# ESP32-S3 register map
Vendor: ESPRESSIF SYSTEMS (SHANGHAI) CO., LTD.; Series: ESP32-S3; File version: 7
CPU: Xtensa LX7 r0p0, little endian, no MPU, FPU, 3 interrupt priority bits
Address unit: 32 bits
Registers are 32-bit, read-write, reset 0x0 unless marked. A register's access mark holds for its fields unless they carry their own. Offsets are from the block's base; [hi:lo] are bit positions; {n}, {i} and the like mark numbered series.

## UHCI0 — Universal Host Controller Interface
Base 0x60014000
Same registers: UHCI1 0x6000C000
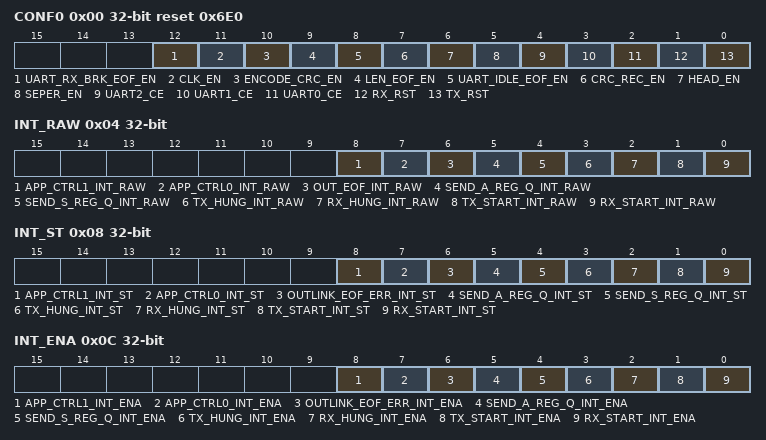
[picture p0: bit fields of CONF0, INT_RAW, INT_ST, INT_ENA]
0x00 CONF0 reset 0x6E0 — UHCI configuration register
  [12] UART_RX_BRK_EOF_EN — If this bit is set to 1, UHCI will end payload receive process when NULL frame is received by UART.
  [11] CLK_EN — 1'b1: Force clock on for register. 1'b0: Support clock only when application writes registers.
  [10] ENCODE_CRC_EN — Set this bit to enable data integrity checking by appending a 16 bit CCITT-CRC to end of the payload.
  [9] LEN_EOF_EN — If this bit is set to 1, UHCI decoder receiving payload data is end when the receiving byte count has reached the specified value. The value is payload length indicated by UHCI packet header when UHCI_HEAD_EN is 1 or the value is configuration value when UHCI_HEAD_EN is 0. If this bit is set to 0, UHCI decoder receiving payload data is end when 0xc0 is received.
  [8] UART_IDLE_EOF_EN — If this bit is set to 1, UHCI will end the payload receiving process when UART has been in idle state.
  [7] CRC_REC_EN — Set this bit to enable UHCI to receive the 16 bit CRC.
  [6] HEAD_EN — Set this bit to encode the data packet with a formatting header.
  [5] SEPER_EN — Set this bit to separate the data frame using a special char.
  [4] UART2_CE — Set this bit to link up HCI and UART2.
  [3] UART1_CE — Set this bit to link up HCI and UART1.
  [2] UART0_CE — Set this bit to link up HCI and UART0.
  [1] RX_RST — Write 1, then write 0 to this bit to reset encode state machine.
  [0] TX_RST — Write 1, then write 0 to this bit to reset decode state machine.
0x04 INT_RAW access per field — Raw interrupt status
  [8] APP_CTRL1_INT_RAW rw — This is the interrupt raw bit. Triggered when set UHCI_APP_CTRL1_IN_SET.
  [7] APP_CTRL0_INT_RAW rw — This is the interrupt raw bit. Triggered when set UHCI_APP_CTRL0_IN_SET.
  [6] OUT_EOF_INT_RAW ro — This is the interrupt raw bit. Triggered when there are some errors in EOF in the transmit data.
  [5] SEND_A_REG_Q_INT_RAW ro — This is the interrupt raw bit. Triggered when UHCI has sent out a short packet using always_send registers.
  [4] SEND_S_REG_Q_INT_RAW ro — This is the interrupt raw bit. Triggered when UHCI has sent out a short packet using single_send registers.
  [3] TX_HUNG_INT_RAW ro — This is the interrupt raw bit. Triggered when UHCI takes more time to read data from RAM than the configured value.
  [2] RX_HUNG_INT_RAW ro — This is the interrupt raw bit. Triggered when UHCI takes more time to receive data than configure value.
  [1] TX_START_INT_RAW ro — This is the interrupt raw bit. Triggered when UHCI detects a separator char.
  [0] RX_START_INT_RAW ro — This is the interrupt raw bit. Triggered when a separator char has been sent.
0x08 INT_ST ro — Masked interrupt status
  [8] APP_CTRL1_INT_ST — This is the masked interrupt bit for UHCI_APP_CTRL1_INT interrupt when UHCI_APP_CTRL1_INT_ENA is set to 1.
  [7] APP_CTRL0_INT_ST — This is the masked interrupt bit for UHCI_APP_CTRL0_INT interrupt when UHCI_APP_CTRL0_INT_ENA is set to 1.
  [6] OUTLINK_EOF_ERR_INT_ST — This is the masked interrupt bit for UHCI_OUTLINK_EOF_ERR_INT interrupt when UHCI_OUTLINK_EOF_ERR_INT_ENA is set to 1.
  [5] SEND_A_REG_Q_INT_ST — This is the masked interrupt bit for UHCI_SEND_A_REQ_Q_INT interrupt when UHCI_SEND_A_REQ_Q_INT_ENA is set to 1.
  [4] SEND_S_REG_Q_INT_ST — This is the masked interrupt bit for UHCI_SEND_S_REQ_Q_INT interrupt when UHCI_SEND_S_REQ_Q_INT_ENA is set to 1.
  [3] TX_HUNG_INT_ST — This is the masked interrupt bit for UHCI_TX_HUNG_INT interrupt when UHCI_TX_HUNG_INT_ENA is set to 1.
  [2] RX_HUNG_INT_ST — This is the masked interrupt bit for UHCI_RX_HUNG_INT interrupt when UHCI_RX_HUNG_INT_ENA is set to 1.
  [1] TX_START_INT_ST — This is the masked interrupt bit for UHCI_TX_START_INT interrupt when UHCI_TX_START_INT_ENA is set to 1.
  [0] RX_START_INT_ST — This is the masked interrupt bit for UHCI_RX_START_INT interrupt when UHCI_RX_START_INT_ENA is set to 1.
0x0C INT_ENA — Interrupt enable bits
  [8] APP_CTRL1_INT_ENA — This is the interrupt enable bit for UHCI_APP_CTRL1_INT interrupt.
  [7] APP_CTRL0_INT_ENA — This is the interrupt enable bit for UHCI_APP_CTRL0_INT interrupt.
  [6] OUTLINK_EOF_ERR_INT_ENA — This is the interrupt enable bit for UHCI_OUTLINK_EOF_ERR_INT interrupt.
  [5] SEND_A_REG_Q_INT_ENA — This is the interrupt enable bit for UHCI_SEND_A_REQ_Q_INT interrupt.
  [4] SEND_S_REG_Q_INT_ENA — This is the interrupt enable bit for UHCI_SEND_S_REQ_Q_INT interrupt.
  [3] TX_HUNG_INT_ENA — This is the interrupt enable bit for UHCI_TX_HUNG_INT interrupt.
  [2] RX_HUNG_INT_ENA — This is the interrupt enable bit for UHCI_RX_HUNG_INT interrupt.
  [1] TX_START_INT_ENA — This is the interrupt enable bit for UHCI_TX_START_INT interrupt.
  [0] RX_START_INT_ENA — This is the interrupt enable bit for UHCI_RX_START_INT interrupt.
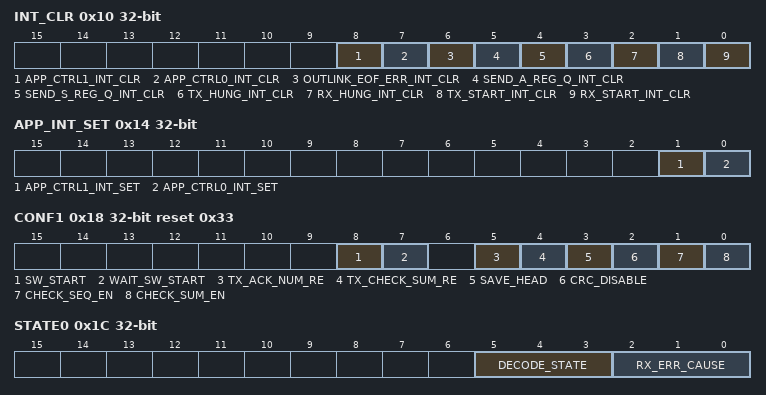
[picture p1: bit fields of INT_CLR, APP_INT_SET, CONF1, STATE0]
0x10 INT_CLR wo — Interrupt clear bits
  [8] APP_CTRL1_INT_CLR — Set this bit to clear UHCI_APP_CTRL1_INT interrupt.
  [7] APP_CTRL0_INT_CLR — Set this bit to clear UHCI_APP_CTRL0_INT interrupt.
  [6] OUTLINK_EOF_ERR_INT_CLR — Set this bit to clear UHCI_OUTLINK_EOF_ERR_INT interrupt.
  [5] SEND_A_REG_Q_INT_CLR — Set this bit to clear UHCI_SEND_A_REQ_Q_INT interrupt.
  [4] SEND_S_REG_Q_INT_CLR — Set this bit to clear UHCI_SEND_S_REQ_Q_INT interrupt.
  [3] TX_HUNG_INT_CLR — Set this bit to clear UHCI_TX_HUNG_INT interrupt.
  [2] RX_HUNG_INT_CLR — Set this bit to clear UHCI_RX_HUNG_INT interrupt.
  [1] TX_START_INT_CLR — Set this bit to clear UHCI_TX_START_INT interrupt.
  [0] RX_START_INT_CLR — Set this bit to clear UHCI_RX_START_INT interrupt.
0x14 APP_INT_SET wo — Software interrupt trigger source
  [1] APP_CTRL1_INT_SET — This bit is software interrupt trigger source of UHCI_APP_CTRL1_INT.
  [0] APP_CTRL0_INT_SET — This bit is software interrupt trigger source of UHCI_APP_CTRL0_INT.
0x18 CONF1 reset 0x33 — UHCI configuration register
  [8] SW_START — If current UHCI_ENCODE_STATE is ST_SW_WAIT, the UHCI will start to send data packet out when this bit is set to 1.
  [7] WAIT_SW_START — The uhci-encoder will jump to ST_SW_WAIT status if this register is set to 1.
  [5] TX_ACK_NUM_RE — Set this bit to encode the data packet with an acknowledgment when a reliable packet is to be transmit.
  [4] TX_CHECK_SUM_RE — Set this bit to encode the data packet with a checksum.
  [3] SAVE_HEAD — Set this bit to save the packet header when HCI receives a data packet.
  [2] CRC_DISABLE — Set this bit to support CRC calculation. Data Integrity Check Present bit in UHCI packet frame should be 1.
  [1] CHECK_SEQ_EN — This is the enable bit to check sequence number when UHCI receives a data packet.
  [0] CHECK_SUM_EN — This is the enable bit to check header checksum when UHCI receives a data packet.
0x1C STATE0 ro — UHCI receive status
  [5:3] DECODE_STATE — UHCI decoder status.
  [2:0] RX_ERR_CAUSE — This register indicates the error type when DMA has received a packet with error. 3'b001: Checksum error in HCI packet. 3'b010: Sequence number error in HCI packet. 3'b011: CRC bit error in HCI packet. 3'b100: 0xc0 is found but received HCI packet is not end. 3'b101: 0xc0 is not found when receiving HCI packet is end. 3'b110: CRC check error.
0x20 STATE1 ro — UHCI transmit status
  [2:0] ENCODE_STATE — UHCI encoder status.
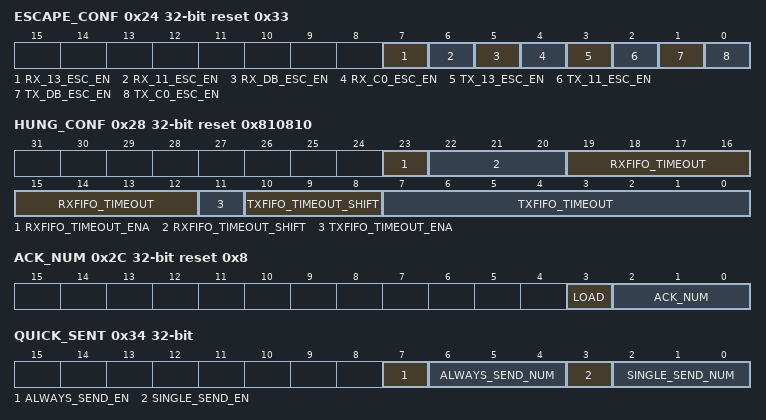
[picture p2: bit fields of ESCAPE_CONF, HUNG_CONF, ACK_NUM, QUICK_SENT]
0x24 ESCAPE_CONF reset 0x33 — Escape character configuration
  [7] RX_13_ESC_EN — Set this bit to enable replacing flow control char 0x13 by special char when DMA sends data.
  [6] RX_11_ESC_EN — Set this bit to enable replacing flow control char 0x11 by special char when DMA sends data.
  [5] RX_DB_ESC_EN — Set this bit to enable replacing 0xdb by special char when DMA sends data.
  [4] RX_C0_ESC_EN — Set this bit to enable replacing 0xc0 by special char when DMA sends data.
  [3] TX_13_ESC_EN — Set this bit to enable decoding flow control char 0x13 when DMA receives data.
  [2] TX_11_ESC_EN — Set this bit to enable decoding flow control char 0x11 when DMA receives data.
  [1] TX_DB_ESC_EN — Set this bit to enable decoding char 0xdb when DMA receives data.
  [0] TX_C0_ESC_EN — Set this bit to enable decoding char 0xc0 when DMA receives data.
0x28 HUNG_CONF reset 0x810810 — Timeout configuration
  [23] RXFIFO_TIMEOUT_ENA — This is the enable bit for DMA send-data timeout.
  [22:20] RXFIFO_TIMEOUT_SHIFT — This register is used to configure the tick count maximum value.
  [19:12] RXFIFO_TIMEOUT — This register stores the timeout value. It will produce the UHCI_RX_HUNG_INT interrupt when DMA takes more time to read data from RAM.
  [11] TXFIFO_TIMEOUT_ENA — This is the enable bit for Tx-FIFO receive-data timeout.
  [10:8] TXFIFO_TIMEOUT_SHIFT — This register is used to configure the tick count maximum value.
  [7:0] TXFIFO_TIMEOUT — This register stores the timeout value. It will produce the UHCI_TX_HUNG_INT interrupt when DMA takes more time to receive data.
0x2C ACK_NUM access per field reset 0x8 — UHCI ACK number configuration
  [3] LOAD wo — Set this bit to 1, the value configured by UHCI_ACK_NUM would be loaded.
  [2:0] ACK_NUM rw — This ACK number used in software flow control.
0x30 RX_HEAD ro — UHCI packet header register
  [31:0] RX_HEAD — This register stores the header of the current received packet.
0x34 QUICK_SENT — UHCI quick send configuration register
  [7] ALWAYS_SEND_EN — Set this bit to enable always_send mode to send short packet.
  [6:4] ALWAYS_SEND_NUM — This register is used to specify the always_send register.
  [3] SINGLE_SEND_EN — Set this bit to enable single_send mode to send short packet.
  [2:0] SINGLE_SEND_NUM — This register is used to specify the single_send register.
{0x38+8i} REG_Q{i}_WORD0 (i=0..6) — Q{i}_WORD0 quick_sent register
  [31:0] SEND_Q{i}_WORD0 — This register is used as a quick_sent register when specified by UHCI_ALWAYS_SEND_NUM or UHCI_SINGLE_SEND_NUM.
{0x3C+8i} REG_Q{i}_WORD1 (i=0..6) — Q{i}_WORD1 quick_sent register
  [31:0] SEND_Q{i}_WORD1 — This register is used as a quick_sent register when specified by UHCI_ALWAYS_SEND_NUM or UHCI_SINGLE_SEND_NUM.
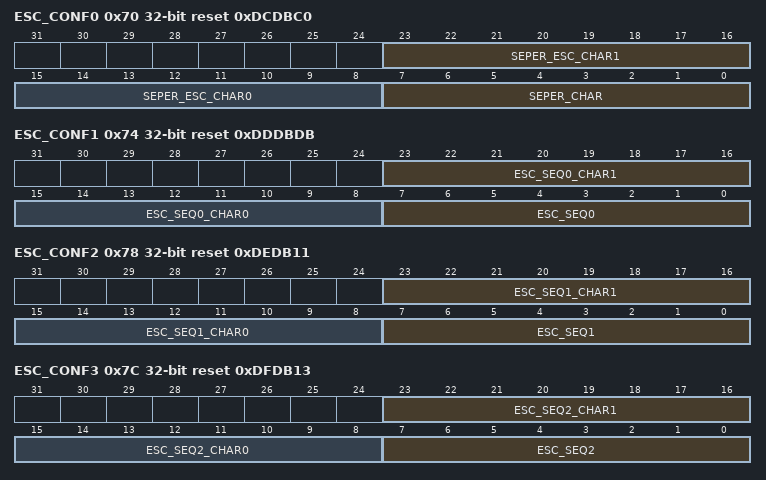
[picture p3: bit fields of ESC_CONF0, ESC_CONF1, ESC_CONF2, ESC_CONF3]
0x70 ESC_CONF0 reset 0xDCDBC0 — Escape sequence configuration register 0
  [23:16] SEPER_ESC_CHAR1 — This register is used to define the second char of slip escape sequence when encoding the separate char, default is 0xdc.
  [15:8] SEPER_ESC_CHAR0 — This register is used to define the first char of slip escape sequence when encoding the separate char, default is 0xdb.
  [7:0] SEPER_CHAR — This register is used to define the separate char that need to be encoded, default is 0xc0.
0x74 ESC_CONF1 reset 0xDDDBDB — Escape sequence configuration register 1
  [23:16] ESC_SEQ0_CHAR1 — This register is used to define the second char of slip escape sequence when encoding the UHCI_ESC_SEQ0, default is 0xdd.
  [15:8] ESC_SEQ0_CHAR0 — This register is used to define the first char of slip escape sequence when encoding the UHCI_ESC_SEQ0, default is 0xdb.
  [7:0] ESC_SEQ0 — This register is used to define a char that need to be encoded, default is 0xdb that used as the first char of slip escape sequence.
0x78 ESC_CONF2 reset 0xDEDB11 — Escape sequence configuration register 2
  [23:16] ESC_SEQ1_CHAR1 — This register is used to define the second char of slip escape sequence when encoding the UHCI_ESC_SEQ1, default is 0xde.
  [15:8] ESC_SEQ1_CHAR0 — This register is used to define the first char of slip escape sequence when encoding the UHCI_ESC_SEQ1, default is 0xdb.
  [7:0] ESC_SEQ1 — This register is used to define a char that need to be encoded, default is 0x11 that used as flow control char.
0x7C ESC_CONF3 reset 0xDFDB13 — Escape sequence configuration register 3
  [23:16] ESC_SEQ2_CHAR1 — This register is used to define the second char of slip escape sequence when encoding the UHCI_ESC_SEQ2, default is 0xdf.
  [15:8] ESC_SEQ2_CHAR0 — This register is used to define the first char of slip escape sequence when encoding the UHCI_ESC_SEQ2, default is 0xdb.
  [7:0] ESC_SEQ2 — This register is used to define a char that need to be decoded, default is 0x13 that used as flow control char.
0x80 PKT_THRES reset 0x80 — Configure register for packet length
  [12:0] PKT_THRS — This register is used to configure the maximum value of the packet length when UHCI_HEAD_EN is 0.
0x84 DATE reset 0x2010090 — UHCI version control register
  [31:0] DATE — This is the version control register.
